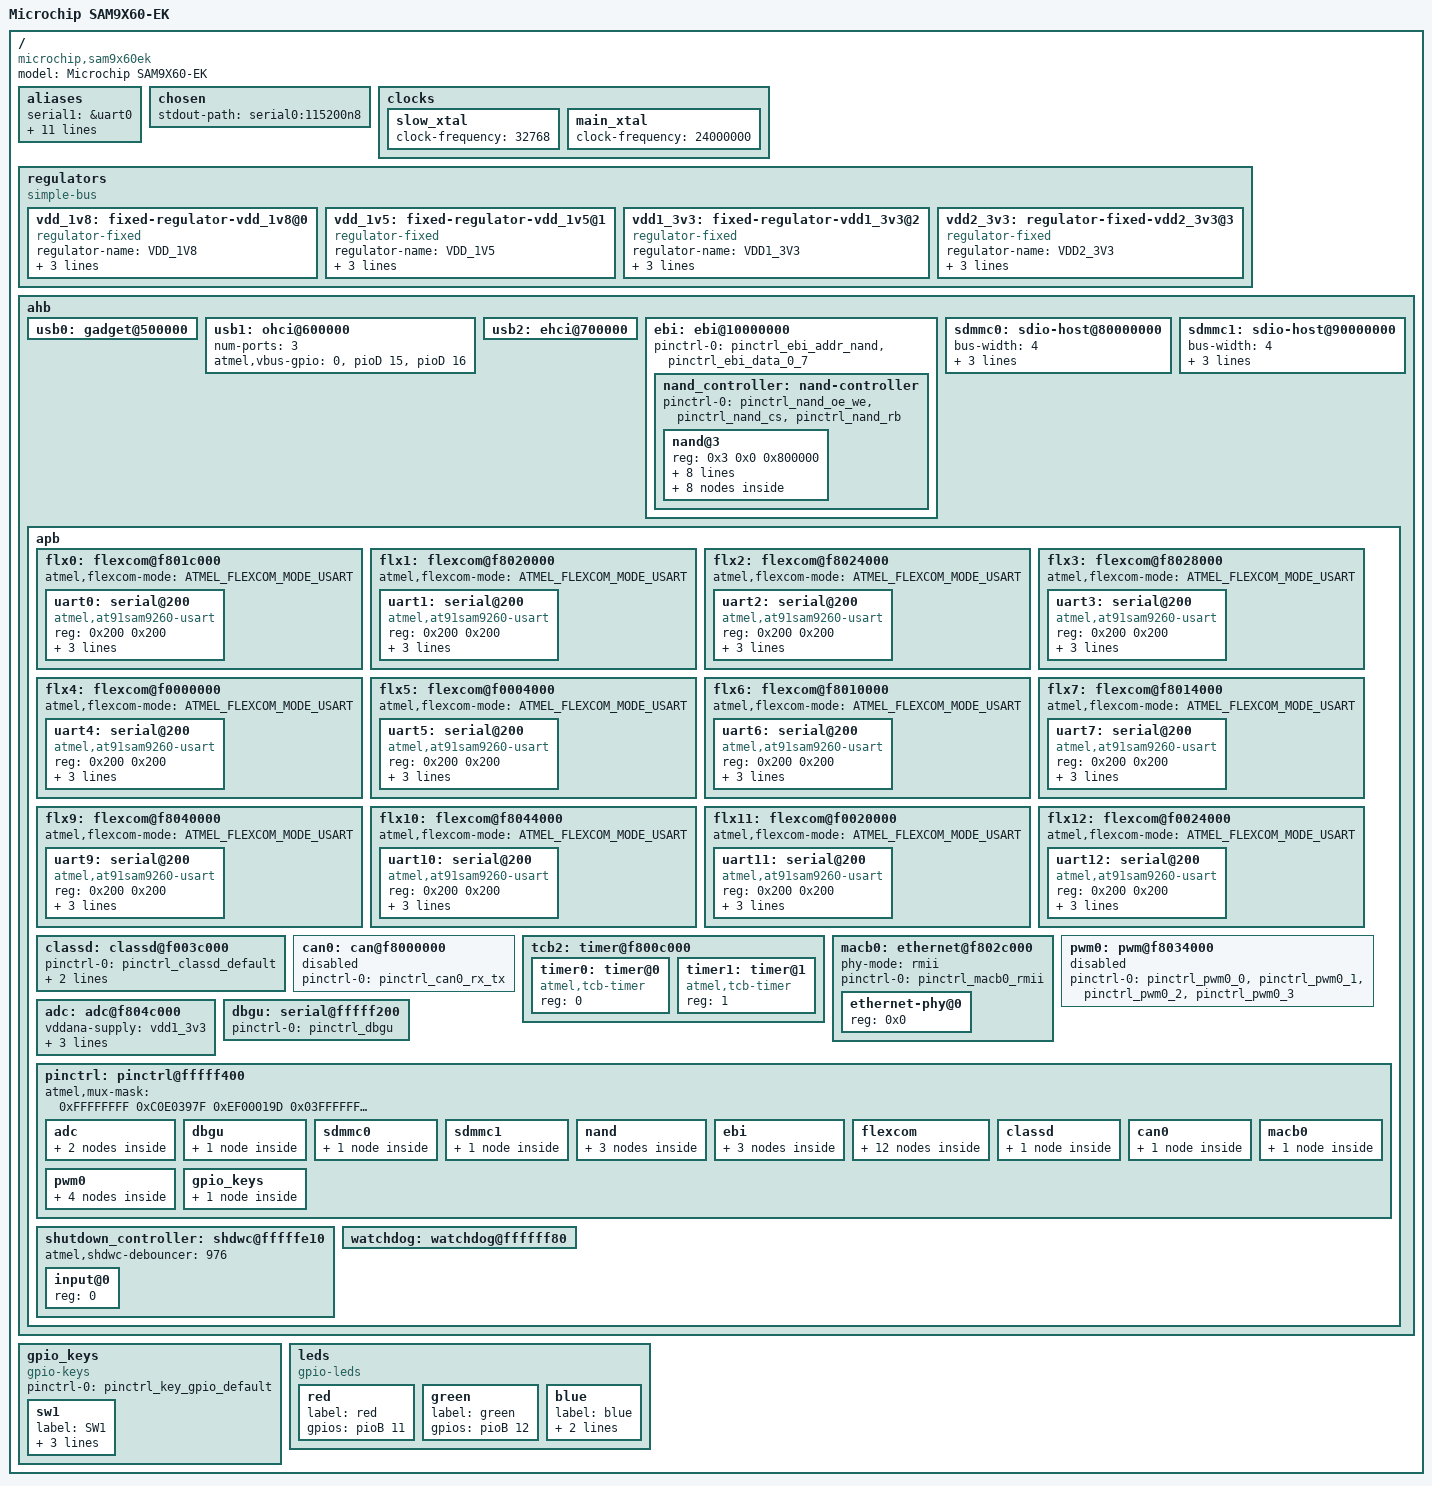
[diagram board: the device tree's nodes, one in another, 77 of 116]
/*
 * at91-sam9x60ek.dts - Device Tree file for SAM9X60 EK board
 *
 *  Copyright (C) 2018 Microchip Technology Inc. and its subsidiaries
 *
 *  Author: Sandeep Sheriker M <sandeepsheriker.mallikarjun@microchip.com>
 */
/dts-v1/;
#include "sam9x60.dtsi"

/ {
	model = "Microchip SAM9X60-EK";
	compatible = "microchip,sam9x60ek", "microchip,sam9x60", "atmel,at91sam9";

	aliases {
		serial1 = &uart0;	// added for adding Flexcom0 UART
		serial2 = &uart1;	// added for adding Flexcom1 UART
		serial3 = &uart2;	// added for adding Flexcom2 UART
		serial4 = &uart3;	// added for adding Flexcom3 UART
		serial5 = &uart4;	// added for adding Flexcom4 UART
		serial6 = &uart5;	// added for adding Flexcom5 UART
		serial7 = &uart6;	// added for adding Flexcom6 UART
		serial8 = &uart7;	// added for adding Flexcom7 UART
		serial9 = &uart9;	// added for adding Flexcom9 UART
		serial10 = &uart10;	// added for adding Flexcom10 UART
		serial11 = &uart11;	// added for adding Flexcom11 UART
		serial12 = &uart12;	// added for adding Flexcom12 UART
	};

	chosen {
		stdout-path = "serial0:115200n8";
	};

	clocks {
		slow_xtal {
			clock-frequency = <32768>;
		};

		main_xtal {
			clock-frequency = <24000000>;
		};
	};

	regulators: regulators {
		compatible = "simple-bus";
		#address-cells = <1>;
		#size-cells = <0>;

		vdd_1v8: fixed-regulator-vdd_1v8@0 {
			compatible = "regulator-fixed";
			regulator-name = "VDD_1V8";
			regulator-min-microvolt = <1800000>;
			regulator-max-microvolt = <1800000>;
			regulator-always-on;
			status = "okay";
		};

		vdd_1v5: fixed-regulator-vdd_1v5@1 {
			compatible = "regulator-fixed";
			regulator-name = "VDD_1V5";
			regulator-min-microvolt = <1500000>;
			regulator-max-microvolt = <1500000>;
			regulator-always-on;
			status = "okay";
		};

		vdd1_3v3: fixed-regulator-vdd1_3v3@2 {
			compatible = "regulator-fixed";
			regulator-name = "VDD1_3V3";
			regulator-min-microvolt = <3300000>;
			regulator-max-microvolt = <3300000>;
			regulator-always-on;
			status = "okay";
		};

		vdd2_3v3: regulator-fixed-vdd2_3v3@3 {
			compatible = "regulator-fixed";
			regulator-name = "VDD2_3V3";
			regulator-min-microvolt = <3300000>;
			regulator-max-microvolt = <3300000>;
			regulator-always-on;
			status = "okay";
		};
	};

	ahb {
		usb0: gadget@500000 {
			status = "okay";
		};

		usb1: ohci@600000 {
			num-ports = <3>;
			atmel,vbus-gpio = <0
					   &pioD 15 GPIO_ACTIVE_HIGH
					   &pioD 16 GPIO_ACTIVE_HIGH>;
			status = "okay";
		};

		usb2: ehci@700000 {
			status = "okay";
		};

		ebi: ebi@10000000 {
			pinctrl-names = "default";
			pinctrl-0 = <&pinctrl_ebi_addr_nand &pinctrl_ebi_data_0_7>;
			status = "okay";

			nand_controller: nand-controller {
				pinctrl-names = "default";
				pinctrl-0 = <&pinctrl_nand_oe_we &pinctrl_nand_cs &pinctrl_nand_rb>;
				status = "okay";

				nand@3 {
					reg = <0x3 0x0 0x800000>;
					rb-gpios = <&pioD 5 GPIO_ACTIVE_HIGH>;
					cs-gpios = <&pioD 4 GPIO_ACTIVE_HIGH>;
					nand-bus-width = <8>;
					nand-ecc-mode = "hw";
					nand-ecc-strength = <8>;
					nand-ecc-step-size = <512>;
					nand-on-flash-bbt;
					label = "atmel_nand";

					partitions {
						compatible = "fixed-partitions";
						#address-cells = <1>;
						#size-cells = <1>;

						at91bootstrap@0 {
							label = "at91bootstrap";
							reg = <0x0 0x40000>;
						};

						uboot@40000 {
							label = "u-boot";
							reg = <0x40000 0xc0000>;
						};

						ubootenvred@100000 {
							label = "U-Boot Env Redundant";
							reg = <0x100000 0x40000>;
						};

						ubootenv@140000 {
							label = "U-Boot Env";
							reg = <0x140000 0x40000>;
						};

						dtb@180000 {
							label = "device tree";
							reg = <0x180000 0x80000>;
						};

						kernel@200000 {
							label = "kernel";
							reg = <0x200000 0x600000>;
						};

						rootfs@800000 {
							label = "rootfs";
							reg = <0x800000 0x1f800000>;
						};
					};
				};
			};
		};

		sdmmc0: sdio-host@80000000 {
			bus-width = <4>;
			pinctrl-names = "default";
			pinctrl-0 = <&pinctrl_sdmmc0_default>;
			status = "okay";
			cd-gpios = <&pioA 23 GPIO_ACTIVE_LOW>;
			disable-wp;
		};

		sdmmc1: sdio-host@90000000 {
			bus-width = <4>;
			pinctrl-names = "default";
			pinctrl-0 = <&pinctrl_sdmmc1_default>;
			no-1-8-v;
			non-removable;
			status = "okay"; /* Conflict with flx4. */
		};

		apb {
			flx0: flexcom@f801c000 {
				atmel,flexcom-mode = <ATMEL_FLEXCOM_MODE_USART>;
				status = "okay";

				uart0: serial@200 {
					compatible = "atmel,at91sam9260-usart";
					reg = <0x200 0x200>;
					interrupts = <5 IRQ_TYPE_LEVEL_HIGH 7>;
					clocks = <&pmc PMC_TYPE_PERIPHERAL 5>;
					clock-names = "usart";
					pinctrl-0 = <&pinctrl_flx0_default>;
					pinctrl-names = "default";
					status = "okay";
				};
			};

			flx1: flexcom@f8020000 {
				atmel,flexcom-mode = <ATMEL_FLEXCOM_MODE_USART>;
				status = "okay";

				uart1: serial@200 {
					compatible = "atmel,at91sam9260-usart";
					reg = <0x200 0x200>;
					interrupts = <6 IRQ_TYPE_LEVEL_HIGH 7>;
					clocks = <&pmc PMC_TYPE_PERIPHERAL 6>;
					clock-names = "usart";
					pinctrl-0 = <&pinctrl_flx1_default>;
					pinctrl-names = "default";
					status = "okay";
				};
			};

			flx2: flexcom@f8024000 {
				atmel,flexcom-mode = <ATMEL_FLEXCOM_MODE_USART>;
				status = "okay";

				uart2: serial@200 {
					compatible = "atmel,at91sam9260-usart";
					reg = <0x200 0x200>;
					interrupts = <7 IRQ_TYPE_LEVEL_HIGH 7>;
					clocks = <&pmc PMC_TYPE_PERIPHERAL 7>;
					clock-names = "usart";
					pinctrl-0 = <&pinctrl_flx2_default>;
					pinctrl-names = "default";
					status = "okay";
				};
			};

			flx3: flexcom@f8028000 {
				atmel,flexcom-mode = <ATMEL_FLEXCOM_MODE_USART>;
				status = "okay";

				uart3: serial@200 {
					compatible = "atmel,at91sam9260-usart";
					reg = <0x200 0x200>;
					interrupts = <8 IRQ_TYPE_LEVEL_HIGH 7>;
					clocks = <&pmc PMC_TYPE_PERIPHERAL 8>;
					clock-names = "usart";
					pinctrl-0 = <&pinctrl_flx3_default>;
					pinctrl-names = "default";
					status = "okay";
				};
			};

			flx4: flexcom@f0000000 {
				atmel,flexcom-mode = <ATMEL_FLEXCOM_MODE_USART>;
				status = "okay";

				uart4: serial@200 {
					compatible = "atmel,at91sam9260-usart";
					reg = <0x200 0x200>;
					interrupts = <13 IRQ_TYPE_LEVEL_HIGH 7>;
					clocks = <&pmc PMC_TYPE_PERIPHERAL 13>;
					clock-names = "usart";
					pinctrl-0 = <&pinctrl_flx4_default>;
					pinctrl-names = "default";
					status = "okay";
				};
			};

			flx5: flexcom@f0004000 {
				atmel,flexcom-mode = <ATMEL_FLEXCOM_MODE_USART>;
				status = "okay";

				uart5: serial@200 {
					compatible = "atmel,at91sam9260-usart";
					reg = <0x200 0x200>;
					interrupts = <14 IRQ_TYPE_LEVEL_HIGH 7>;
					clocks = <&pmc PMC_TYPE_PERIPHERAL 14>;
					clock-names = "usart";
					pinctrl-0 = <&pinctrl_flx5_default>;
					pinctrl-names = "default";
					status = "okay";
				};
			};

			flx6: flexcom@f8010000 {
				atmel,flexcom-mode = <ATMEL_FLEXCOM_MODE_USART>;
				status = "okay";

				uart6: serial@200 {
					compatible = "atmel,at91sam9260-usart";
					reg = <0x200 0x200>;
					interrupts = <9 IRQ_TYPE_LEVEL_HIGH 7>;
					clocks = <&pmc PMC_TYPE_PERIPHERAL 9>;
					clock-names = "usart";
					pinctrl-0 = <&pinctrl_flx6_default>;
					pinctrl-names = "default";
					status = "okay";
				};
			};

			flx7: flexcom@f8014000 {
				atmel,flexcom-mode = <ATMEL_FLEXCOM_MODE_USART>;
				status = "okay";

				uart7: serial@200 {
					compatible = "atmel,at91sam9260-usart";
					reg = <0x200 0x200>;
					interrupts = <10 IRQ_TYPE_LEVEL_HIGH 7>;
					clocks = <&pmc PMC_TYPE_PERIPHERAL 10>;
					clock-names = "usart";
					pinctrl-0 = <&pinctrl_flx7_default>;
					pinctrl-names = "default";
					status = "okay";
				};
			};

			flx9: flexcom@f8040000 {
				atmel,flexcom-mode = <ATMEL_FLEXCOM_MODE_USART>;
				status = "okay";

				uart9: serial@200 {
					compatible = "atmel,at91sam9260-usart";
					reg = <0x200 0x200>;
					interrupts = <15 IRQ_TYPE_LEVEL_HIGH 7>;
					clocks = <&pmc PMC_TYPE_PERIPHERAL 15>;
					clock-names = "usart";
					pinctrl-0 = <&pinctrl_flx9_default>;
					pinctrl-names = "default";
					status = "okay";
				};
			};

			flx10: flexcom@f8044000 {
				atmel,flexcom-mode = <ATMEL_FLEXCOM_MODE_USART>;
				status = "okay";

				uart10: serial@200 {
					compatible = "atmel,at91sam9260-usart";
					reg = <0x200 0x200>;
					interrupts = <16 IRQ_TYPE_LEVEL_HIGH 7>;
					clocks = <&pmc PMC_TYPE_PERIPHERAL 16>;
					clock-names = "usart";
					pinctrl-0 = <&pinctrl_flx10_default>;
					pinctrl-names = "default";
					status = "okay";
				};
			};

			flx11: flexcom@f0020000 {
				atmel,flexcom-mode = <ATMEL_FLEXCOM_MODE_USART>;
				status = "okay";

				uart11: serial@200 {
					compatible = "atmel,at91sam9260-usart";
					reg = <0x200 0x200>;
					interrupts = <32 IRQ_TYPE_LEVEL_HIGH 7>;
					clocks = <&pmc PMC_TYPE_PERIPHERAL 32>;
					clock-names = "usart";
					pinctrl-0 = <&pinctrl_flx11_default>;
					pinctrl-names = "default";
					status = "okay";
				};
			};

			flx12: flexcom@f0024000 {
				atmel,flexcom-mode = <ATMEL_FLEXCOM_MODE_USART>;
				status = "okay";

				uart12: serial@200 {
					compatible = "atmel,at91sam9260-usart";
					reg = <0x200 0x200>;
					interrupts = <33 IRQ_TYPE_LEVEL_HIGH 7>;
					clocks = <&pmc PMC_TYPE_PERIPHERAL 33>;
					clock-names = "usart";
					pinctrl-0 = <&pinctrl_flx12_default>;
					pinctrl-names = "default";
					status = "okay";
				};
			};

			classd: classd@f003c000 {
				pinctrl-names = "default";
				pinctrl-0 = <&pinctrl_classd_default>;
				atmel,pwm-type = "diff";
				atmel,non-overlap-time = <10>;
				status = "okay";
			};

			can0: can@f8000000 {
				pinctrl-names = "default";
				pinctrl-0 = <&pinctrl_can0_rx_tx>;
				status = "disabled"; /* Conflict with dbgu. */
			};

			tcb2: timer@f800c000 {
				timer0: timer@0 {
					compatible = "atmel,tcb-timer";
					reg = <0>;
				};

				timer1: timer@1 {
					compatible = "atmel,tcb-timer";
					reg = <1>;
				};
			};

			macb0: ethernet@f802c000 {
				phy-mode = "rmii";
				#address-cells = <1>;
				#size-cells = <0>;
				pinctrl-names = "default";
				pinctrl-0 = <&pinctrl_macb0_rmii>;
				status = "okay";

				ethernet-phy@0 {
					reg = <0x0>;
				};
			};

			pwm0: pwm@f8034000 {
				pinctrl-names = "default";
				pinctrl-0 = <&pinctrl_pwm0_0 &pinctrl_pwm0_1 &pinctrl_pwm0_2 &pinctrl_pwm0_3>;
				status = "disabled"; /* Conflict with leds. */
			};

			adc: adc@f804c000 {
				vddana-supply = <&vdd1_3v3>;
				vref-supply = <&vdd1_3v3>;
				pinctrl-names = "default";
				pinctrl-0 = <&pinctrl_adc_default &pinctrl_adtrg_default>;
				status = "okay";
			};

			dbgu: serial@fffff200 {
				pinctrl-names = "default";
				pinctrl-0 = <&pinctrl_dbgu>;
				status = "okay"; /* Conflict with can0. */
			};

			pinctrl: pinctrl@fffff400 {
				atmel,mux-mask = <
						 /*	A	B	C	*/
						 0xFFFFFFFF 0xC0E0397F 0xEF00019D	/* pioA */
						 0x03FFFFFF 0x02FC7E68 0x007C0000	/* pioB */
						 0xffffffff 0xF8FFFFFF 0xB803F3FF	/* pioC */
						 0x003FFFFF 0x003F8000 0x00000000	/* pioD */
						 >;

				adc {
					pinctrl_adc_default: adc_default {
						atmel,pins =
								<AT91_PIOB 15 AT91_PERIPH_A AT91_PINCTRL_NONE>;
					};

					pinctrl_adtrg_default: adtrg_default {
						atmel,pins =
								<AT91_PIOB 18 AT91_PERIPH_B AT91_PINCTRL_PULL_UP>;
					};
				};

				dbgu {
					pinctrl_dbgu: dbgu-0 {
						atmel,pins =
							<AT91_PIOA 9 AT91_PERIPH_A AT91_PINCTRL_PULL_UP
							 AT91_PIOA 10 AT91_PERIPH_A AT91_PINCTRL_NONE>;
					};
				};

				sdmmc0 {
					pinctrl_sdmmc0_default: sdmmc0 {
						atmel,pins =
							<AT91_PIOA 17 AT91_PERIPH_A (AT91_PINCTRL_DRIVE_STRENGTH_HI | AT91_PINCTRL_SLEWRATE_ENA)			/* PA17 CK  periph A with pullup */
							 AT91_PIOA 16 AT91_PERIPH_A (AT91_PINCTRL_PULL_UP | AT91_PINCTRL_DRIVE_STRENGTH_HI | AT91_PINCTRL_SLEWRATE_ENA)	/* PA16 CMD periph A with pullup */
							 AT91_PIOA 15 AT91_PERIPH_A (AT91_PINCTRL_PULL_UP | AT91_PINCTRL_DRIVE_STRENGTH_HI | AT91_PINCTRL_SLEWRATE_ENA)	/* PA15 DAT0 periph A */
							 AT91_PIOA 18 AT91_PERIPH_A (AT91_PINCTRL_PULL_UP | AT91_PINCTRL_DRIVE_STRENGTH_HI | AT91_PINCTRL_SLEWRATE_ENA)	/* PA18 DAT1 periph A with pullup */
							 AT91_PIOA 19 AT91_PERIPH_A (AT91_PINCTRL_PULL_UP | AT91_PINCTRL_DRIVE_STRENGTH_HI | AT91_PINCTRL_SLEWRATE_ENA)	/* PA19 DAT2 periph A with pullup */
							 AT91_PIOA 20 AT91_PERIPH_A (AT91_PINCTRL_PULL_UP | AT91_PINCTRL_DRIVE_STRENGTH_HI | AT91_PINCTRL_SLEWRATE_ENA)>; /* PA20 DAT3 periph A with pullup */
					};
				};

				sdmmc1 {
					pinctrl_sdmmc1_default: sdmmc1 {
						atmel,pins =
							<AT91_PIOA 13 AT91_PERIPH_B (AT91_PINCTRL_DRIVE_STRENGTH_HI | AT91_PINCTRL_SLEWRATE_ENA)				/* PA13 CK periph B */
							 AT91_PIOA 12 AT91_PERIPH_B (AT91_PINCTRL_PULL_UP | AT91_PINCTRL_DRIVE_STRENGTH_HI | AT91_PINCTRL_SLEWRATE_ENA)	/* PA12 CMD periph B with pullup */
							 AT91_PIOA 11 AT91_PERIPH_B (AT91_PINCTRL_PULL_UP | AT91_PINCTRL_DRIVE_STRENGTH_HI | AT91_PINCTRL_SLEWRATE_ENA)	/* PA11 DAT0 periph B with pullup */
							 AT91_PIOA 2 AT91_PERIPH_B (AT91_PINCTRL_PULL_UP | AT91_PINCTRL_DRIVE_STRENGTH_HI | AT91_PINCTRL_SLEWRATE_ENA)	/* PA2 DAT1 periph B with pullup */
							 AT91_PIOA 3 AT91_PERIPH_B (AT91_PINCTRL_PULL_UP | AT91_PINCTRL_DRIVE_STRENGTH_HI | AT91_PINCTRL_SLEWRATE_ENA)	/* PA3 DAT2 periph B with pullup */
							 AT91_PIOA 4 AT91_PERIPH_B (AT91_PINCTRL_PULL_UP | AT91_PINCTRL_DRIVE_STRENGTH_HI | AT91_PINCTRL_SLEWRATE_ENA)>;	/* PA4 DAT3 periph B with pullup */
					};
				};

				nand {
					pinctrl_nand_oe_we: nand-oe-we-0 {
						atmel,pins =
							<AT91_PIOD 0 AT91_PERIPH_A (AT91_PINCTRL_NONE | AT91_PINCTRL_SLEWRATE_DIS)
							 AT91_PIOD 1 AT91_PERIPH_A (AT91_PINCTRL_NONE | AT91_PINCTRL_SLEWRATE_DIS)>;
					};

					pinctrl_nand_rb: nand-rb-0 {
						atmel,pins =
							<AT91_PIOD 5 AT91_PERIPH_GPIO AT91_PINCTRL_PULL_UP>;
					};

					pinctrl_nand_cs: nand-cs-0 {
						atmel,pins =
							<AT91_PIOD 4 AT91_PERIPH_GPIO AT91_PINCTRL_PULL_UP>;
					};
				};

				ebi {
					pinctrl_ebi_data_0_7: ebi-data-lsb-0 {
						atmel,pins =
							<AT91_PIOD 6 AT91_PERIPH_A (AT91_PINCTRL_NONE | AT91_PINCTRL_SLEWRATE_DIS)
							 AT91_PIOD 7 AT91_PERIPH_A (AT91_PINCTRL_NONE | AT91_PINCTRL_SLEWRATE_DIS)
							 AT91_PIOD 8 AT91_PERIPH_A (AT91_PINCTRL_NONE | AT91_PINCTRL_SLEWRATE_DIS)
							 AT91_PIOD 9 AT91_PERIPH_A (AT91_PINCTRL_NONE | AT91_PINCTRL_SLEWRATE_DIS)
							 AT91_PIOD 10 AT91_PERIPH_A (AT91_PINCTRL_NONE | AT91_PINCTRL_SLEWRATE_DIS)
							 AT91_PIOD 11 AT91_PERIPH_A (AT91_PINCTRL_NONE | AT91_PINCTRL_SLEWRATE_DIS)
							 AT91_PIOD 12 AT91_PERIPH_A (AT91_PINCTRL_NONE | AT91_PINCTRL_SLEWRATE_DIS)
							 AT91_PIOD 13 AT91_PERIPH_A (AT91_PINCTRL_NONE | AT91_PINCTRL_SLEWRATE_DIS)>;
					};

					pinctrl_ebi_data_0_15: ebi-data-msb-0 {
						atmel,pins =
							<AT91_PIOD 6 AT91_PERIPH_A AT91_PINCTRL_NONE
							 AT91_PIOD 7 AT91_PERIPH_A AT91_PINCTRL_NONE
							 AT91_PIOD 8 AT91_PERIPH_A AT91_PINCTRL_NONE
							 AT91_PIOD 9 AT91_PERIPH_A AT91_PINCTRL_NONE
							 AT91_PIOD 10 AT91_PERIPH_A AT91_PINCTRL_NONE
							 AT91_PIOD 11 AT91_PERIPH_A AT91_PINCTRL_NONE
							 AT91_PIOD 12 AT91_PERIPH_A AT91_PINCTRL_NONE
							 AT91_PIOD 13 AT91_PERIPH_A AT91_PINCTRL_NONE
							 AT91_PIOD 14 AT91_PERIPH_A AT91_PINCTRL_NONE
							 AT91_PIOD 15 AT91_PERIPH_A AT91_PINCTRL_NONE
							 AT91_PIOD 16 AT91_PERIPH_A AT91_PINCTRL_NONE
							 AT91_PIOD 17 AT91_PERIPH_A AT91_PINCTRL_NONE
							 AT91_PIOD 18 AT91_PERIPH_A AT91_PINCTRL_NONE
							 AT91_PIOD 19 AT91_PERIPH_A AT91_PINCTRL_NONE
							 AT91_PIOD 20 AT91_PERIPH_A AT91_PINCTRL_NONE
							 AT91_PIOD 21 AT91_PERIPH_A AT91_PINCTRL_NONE>;
					};

					pinctrl_ebi_addr_nand: ebi-addr-0 {
						atmel,pins =
							<AT91_PIOD 2 AT91_PERIPH_A (AT91_PINCTRL_NONE | AT91_PINCTRL_SLEWRATE_DIS)
							 AT91_PIOD 3 AT91_PERIPH_A (AT91_PINCTRL_NONE | AT91_PINCTRL_SLEWRATE_DIS)>;
					};
				};

				flexcom {
					pinctrl_flx0_default: flx0_uart {
						atmel,pins =
							<AT91_PIOA 0 AT91_PERIPH_A AT91_PINCTRL_PULL_UP
							 AT91_PIOA 1 AT91_PERIPH_A AT91_PINCTRL_PULL_UP>;
					};

					pinctrl_flx1_default: flx1_uart {
						atmel,pins =
							 <AT91_PIOA 5 AT91_PERIPH_A AT91_PINCTRL_NONE
							 AT91_PIOA 6 AT91_PERIPH_A AT91_PINCTRL_NONE>;
					};

					pinctrl_flx2_default: flx2_uart {
						atmel,pins =
							 <AT91_PIOA 7 AT91_PERIPH_A AT91_PINCTRL_NONE
							 AT91_PIOA 8 AT91_PERIPH_A AT91_PINCTRL_NONE>;
					};

					pinctrl_flx3_default: flx3_uart {
						atmel,pins =
							 <AT91_PIOC 22 AT91_PERIPH_B AT91_PINCTRL_NONE
							 AT91_PIOC 23 AT91_PERIPH_B AT91_PINCTRL_NONE>;
					};

					pinctrl_flx4_default: flx4_uart {
						atmel,pins =
							 <AT91_PIOA 12 AT91_PERIPH_A AT91_PINCTRL_NONE
							 AT91_PIOA 11 AT91_PERIPH_A AT91_PINCTRL_NONE>;
					};

					pinctrl_flx6_default: flx6_uart {
						atmel,pins =
							<AT91_PIOA 30 AT91_PERIPH_A AT91_PINCTRL_PULL_UP
							 AT91_PIOA 31 AT91_PERIPH_A AT91_PINCTRL_PULL_UP>;
					};

					pinctrl_flx7_default: flx7_uart {
						atmel,pins =
							 <AT91_PIOC 0 AT91_PERIPH_C AT91_PINCTRL_NONE
							 AT91_PIOC 1 AT91_PERIPH_C AT91_PINCTRL_NONE>;
					};

					pinctrl_flx9_default: flx9_uart {
						atmel,pins =
							 <AT91_PIOC 8 AT91_PERIPH_C AT91_PINCTRL_NONE
							 AT91_PIOC 9 AT91_PERIPH_C AT91_PINCTRL_NONE>;
					};

					pinctrl_flx10_default: flx10_uart {
						atmel,pins =
							 <AT91_PIOC 16 AT91_PERIPH_C AT91_PINCTRL_NONE
							 AT91_PIOC 17 AT91_PERIPH_C AT91_PINCTRL_NONE>;
					};

					pinctrl_flx11_default: flx11_uart {
						atmel,pins =
							 <AT91_PIOB 19 AT91_PERIPH_C AT91_PINCTRL_NONE
							 AT91_PIOB 20 AT91_PERIPH_C AT91_PINCTRL_NONE>;
					};

					pinctrl_flx12_default: flx12_uart {
						atmel,pins =
							 <AT91_PIOB 21 AT91_PERIPH_C AT91_PINCTRL_NONE
							 AT91_PIOB 22 AT91_PERIPH_C AT91_PINCTRL_NONE>;
					};

					pinctrl_flx5_default: flx5_uart {
						atmel,pins =
							 <AT91_PIOA 21 AT91_PERIPH_B AT91_PINCTRL_NONE
							 AT91_PIOA 22 AT91_PERIPH_B AT91_PINCTRL_NONE>;
					};
				};

				classd {
					pinctrl_classd_default: classd {
						atmel,pins =
							<AT91_PIOA 24 AT91_PERIPH_C AT91_PINCTRL_PULL_UP
							 AT91_PIOA 25 AT91_PERIPH_C AT91_PINCTRL_PULL_UP
							 AT91_PIOA 26 AT91_PERIPH_C AT91_PINCTRL_PULL_UP
							 AT91_PIOA 27 AT91_PERIPH_C AT91_PINCTRL_PULL_UP>;
					};
				};

				can0 {
					pinctrl_can0_rx_tx: can0_rx_tx {
						atmel,pins =
							<AT91_PIOA 9 AT91_PERIPH_B AT91_PINCTRL_NONE	/* CANRX0 */
							 AT91_PIOA 10 AT91_PERIPH_B AT91_PINCTRL_NONE	/* CANTX0 */
							 AT91_PIOD 20 AT91_PERIPH_GPIO AT91_PINCTRL_PULL_DOWN	/* Enable CAN0 mux */
							 AT91_PIOD 21 AT91_PERIPH_GPIO AT91_PINCTRL_PULL_DOWN>;	/* Enable CAN Transceivers */
					};
				};

				macb0 {
					pinctrl_macb0_rmii: macb0_rmii-0 {
						atmel,pins =
							<AT91_PIOB 0 AT91_PERIPH_A AT91_PINCTRL_NONE	/* PB0 periph A */
							 AT91_PIOB 1 AT91_PERIPH_A AT91_PINCTRL_NONE	/* PB1 periph A */
							 AT91_PIOB 2 AT91_PERIPH_A AT91_PINCTRL_NONE	/* PB2 periph A */
							 AT91_PIOB 3 AT91_PERIPH_A AT91_PINCTRL_NONE	/* PB3 periph A */
							 AT91_PIOB 4 AT91_PERIPH_A AT91_PINCTRL_NONE	/* PB4 periph A */
							 AT91_PIOB 5 AT91_PERIPH_A AT91_PINCTRL_NONE	/* PB5 periph A */
							 AT91_PIOB 6 AT91_PERIPH_A AT91_PINCTRL_NONE	/* PB6 periph A */
							 AT91_PIOB 7 AT91_PERIPH_A AT91_PINCTRL_NONE	/* PB7 periph A */
							 AT91_PIOB 9 AT91_PERIPH_A AT91_PINCTRL_NONE	/* PB9 periph A */
							 AT91_PIOB 10 AT91_PERIPH_A AT91_PINCTRL_NONE>;	/* PB10 periph A */
					};
				};

				pwm0 {
					pinctrl_pwm0_0: pwm0_0 {
						atmel,pins =
							<AT91_PIOB 11 AT91_PERIPH_B AT91_PINCTRL_NONE>;
					};

					pinctrl_pwm0_1: pwm0_1 {
						atmel,pins =
							<AT91_PIOB 12 AT91_PERIPH_B AT91_PINCTRL_NONE>;
					};

					pinctrl_pwm0_2: pwm0_2 {
						atmel,pins =
							<AT91_PIOB 13 AT91_PERIPH_B AT91_PINCTRL_NONE>;
					};

					pinctrl_pwm0_3: pwm0_3 {
						atmel,pins =
							<AT91_PIOB 14 AT91_PERIPH_B AT91_PINCTRL_NONE>;
					};
				};

				gpio_keys {
					pinctrl_key_gpio_default: pinctrl_key_gpio {
						atmel,pins =
							<AT91_PIOD 18 AT91_PERIPH_GPIO AT91_PINCTRL_NONE>;
					};
				};
			}; /* pinctrl */

			shutdown_controller: shdwc@fffffe10 {
				atmel,shdwc-debouncer = <976>;
				status = "okay";

				input@0 {
					reg = <0>;
				};
			};

			watchdog: watchdog@ffffff80 {
				status = "okay";
			};
		}; /* apb */
	}; /*ahb */

	gpio_keys {
		compatible = "gpio-keys";
		pinctrl-names = "default";
		pinctrl-0 = <&pinctrl_key_gpio_default>;
		status = "okay";

		sw1 {
			label = "SW1";
			gpios = <&pioD 18 GPIO_ACTIVE_LOW>;
			linux,code=<0x104>;
			wakeup-source;
		};
	};

	leds {
		compatible = "gpio-leds";
		status = "okay"; /* Conflict with pwm0. */

		red {
			label = "red";
			gpios = <&pioB 11 GPIO_ACTIVE_HIGH>;
		};

		green {
			label = "green";
			gpios = <&pioB 12 GPIO_ACTIVE_HIGH>;
		};

		blue {
			label = "blue";
			gpios = <&pioB 13 GPIO_ACTIVE_HIGH>;
			linux,default-trigger = "heartbeat";
		};
	};
};
